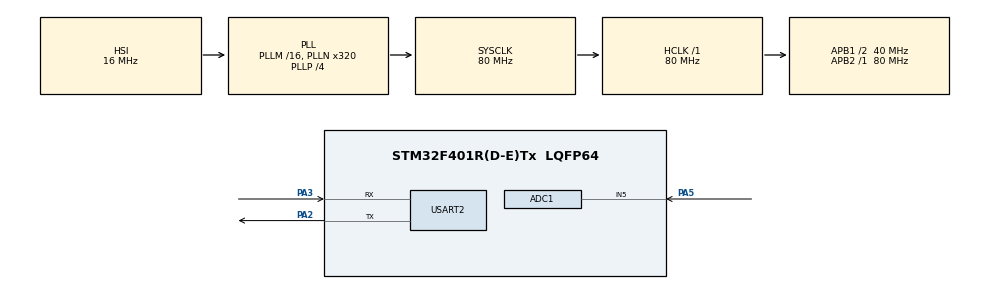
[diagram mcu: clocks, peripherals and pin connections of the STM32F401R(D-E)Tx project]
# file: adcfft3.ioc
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ADC1.Channel-1\#ChannelRegularConversion=ADC_CHANNEL_5
ADC1.ExternalTrigConv=ADC_EXTERNALTRIGCONV_T2_TRGO
ADC1.NbrOfConversionFlag=1
ADC1.Rank-1\#ChannelRegularConversion=1
ADC1.SamplingTime-1\#ChannelRegularConversion=ADC_SAMPLETIME_3CYCLES
ADC1.master=1
Mcu.Family=STM32F4
Mcu.Name=STM32F401R(D-E)Tx
Mcu.Package=LQFP64
NVIC.ADC_IRQn=true\:0\:0\:false\:false\:true\:true\:true\:true
NVIC.PriorityGroup=NVIC_PRIORITYGROUP_4
NVIC.TIM2_IRQn=true\:0\:0\:false\:false\:true\:true\:true\:true
NVIC.TIM3_IRQn=true\:0\:0\:false\:false\:true\:true\:true\:true
PA2.Mode=Asynchronous
PA2.Signal=USART2_TX
PA3.Mode=Asynchronous
PA3.Signal=USART2_RX
PA5.Signal=ADCx_IN5
ProjectManager.HeapSize=0x200
ProjectManager.StackSize=0x400
ProjectManager.TargetToolchain=STM32CubeIDE
RCC.48MHZClocksFreq_Value=80000000
RCC.AHBFreq_Value=80000000
RCC.APB1CLKDivider=RCC_HCLK_DIV2
RCC.APB1Freq_Value=40000000
RCC.APB1TimFreq_Value=80000000
RCC.APB2Freq_Value=80000000
RCC.APB2TimFreq_Value=80000000
RCC.CortexFreq_Value=80000000
RCC.HCLKFreq_Value=80000000
RCC.HSE_VALUE=25000000
RCC.HSI_VALUE=16000000
RCC.LSE_VALUE=32768
RCC.PLLN=320
RCC.PLLP=RCC_PLLP_DIV4
RCC.SYSCLKFreq_VALUE=80000000
RCC.SYSCLKSource=RCC_SYSCLKSOURCE_PLLCLK
RCC.VCOOutputFreq_Value=320000000
SH.ADCx_IN5.0=ADC1_IN5,IN5
TIM2.Channel-PWM\ Generation1\ No\ Output=TIM_CHANNEL_1
TIM2.Period=400
TIM2.TIM_MasterOutputTrigger=TIM_TRGO_UPDATE
TIM2.TIM_MasterSlaveMode=TIM_MASTERSLAVEMODE_DISABLE
TIM3.ClockDivision=TIM_CLOCKDIVISION_DIV4
TIM3.Period=40960
TIM3.Prescaler=7
USART2.VirtualMode=VM_ASYNC
VP_TIM2_VS_ClockSourceINT.Mode=Internal
VP_TIM2_VS_no_output1.Mode=PWM Generation1 No Output
VP_TIM3_VS_ClockSourceINT.Mode=Internal
board=custom

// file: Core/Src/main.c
/* USER CODE BEGIN Header */
/**
  ******************************************************************************
  * @file           : main.c
  * @brief          : Main program body
  ******************************************************************************
  * @attention
  *
  * Copyright (c) 2025 STMicroelectronics.
  * All rights reserved.
  *
  * This software is licensed under terms that can be found in the LICENSE file
  * in the root directory of this software component.
  * If no LICENSE file comes with this software, it is provided AS-IS.
  *
  ******************************************************************************
  */
/* USER CODE END Header */
#include "main.h"

/* USER CODE BEGIN Includes */
#include "stdbool.h"
#include <string.h>
#include "arm_math.h"
#include "stm32f4xx_it.h"
#include "string.h"
/* USER CODE END Includes */

ADC_HandleTypeDef hadc1;

TIM_HandleTypeDef htim2;
TIM_HandleTypeDef htim3;

UART_HandleTypeDef huart2;

/* USER CODE BEGIN PV */
extern int val_from_adc;
extern float32_t adc_val_array1[FFT_N];
extern float32_t adc_val_array2[FFT_N];
extern bool inputtingarray2;
extern uint32_t adc_arrayindex;
extern bool timer3calcfft;

int message[MESSAGE_LENGTH];
uint32_t messageindex;
float32_t fft_val_array[2* FFT_N];
float32_t fft_val_array_magnitude[FFT_N];
/* USER CODE END PV */

void SystemClock_Config(void);
static void MX_GPIO_Init(void);
static void MX_ADC1_Init(void);
static void MX_TIM2_Init(void);
static void MX_TIM3_Init(void);
static void MX_USART2_UART_Init(void);

/* USER CODE BEGIN 0 */
int _write(int file, char *ptr, int len) {
  /* Implement your write code here, this is used by puts and printf for example */
  int i=0;
  for(i=0 ; i<len ; i++)
  ITM_SendChar((*ptr++));
  return len;
}

/* USER CODE END 0 */

int main(void)
{

  /* MCU Configuration--------------------------------------------------------*/

  /* Reset of all peripherals, Initializes the Flash interface and the Systick. */
  HAL_Init();

  /* Configure the system clock */
  SystemClock_Config();

  /* Initialize all configured peripherals */
  MX_GPIO_Init();
  MX_ADC1_Init();
  MX_TIM2_Init();
  MX_TIM3_Init();
  MX_USART2_UART_Init();
  /* USER CODE BEGIN 2 */
  HAL_ADC_Start_IT(&hadc1);
  HAL_TIM_Base_Start_IT(&htim2);
  HAL_TIM_Base_Start_IT(&htim3);

  arm_cfft_instance_f32 S;
//  uint32_t fftSize = FFT_N;
  uint32_t ifftFlag = 0;
  uint32_t doBitReverse = 1;

//  uint32_t testIndex = 0;
//  float32_t maxValue;

//  arm_status status = arm_cfft_radix4_init_f32 (&S, fftSize, ifftFlag, doBitReverse);
  arm_cfft_init_f32(&S, FFT_N);
  messageindex = 0;

  while(!inputtingarray2); // first time inputting into array 1 (not necessary)

  /* USER CODE END 2 */

  /* Infinite loop */
  while (1)
  {

    /* USER CODE BEGIN 3 */
	if (timer3calcfft) {
//	  memset(fft_val_array, 0, FFT_N * sizeof(fft_val_array[0]));
	  if (inputtingarray2) {
//		memcpy(fft_val_array, adc_val_array1, FFT_N * sizeof(adc_val_array1[0]));
		for (int i = 0; i < FFT_N; i++) {
          fft_val_array[2*i] = adc_val_array1[i];
          fft_val_array[2*i + 1] = 0;
		}
	  } else {
//		memcpy(fft_val_array, adc_val_array2, FFT_N * sizeof(adc_val_array2[0]));
	    for (int i = 0; i < FFT_N; i++) {
		  fft_val_array[2*i] = adc_val_array2[i];
          fft_val_array[2*i + 1] = 0;
		}
	  }
	  arm_cfft_f32(&S, fft_val_array, ifftFlag, doBitReverse);
	  arm_cmplx_mag_f32(fft_val_array, fft_val_array_magnitude, FFT_N);
//	  arm_cfft_radix4_f32 (&S, fft_val_array);                      // FFT transform
//	  arm_cmplx_mag_f32 (fft_val_array, fft_val_array_magnitude, fftSize);       // recalculate to Magn./Phase representation
//	  arm_max_f32 (fft_val_array_magnitude, fftSize, &maxValue, &testIndex); // find maxValue and returns it's index (bin) value
	  timer3calcfft = 0;

	  if (messageindex <= MESSAGE_LENGTH) {
		int bit0twotrue = ((fft_val_array_magnitude[FREQ0INDEX2] > RECEIVE0THRESHOLDTWO) ? 1:0) +
				((fft_val_array_magnitude[FREQ0INDEX3] > RECEIVE0THRESHOLDTWO) ? 1:0) +
				((fft_val_array_magnitude[FREQ0INDEX4] > RECEIVE0THRESHOLDTWO) ? 1:0);
		int bit1twotrue = (fft_val_array_magnitude[FREQ1INDEX1] > RECEIVE1THRESHOLD) ? 1:0 +
	    		(fft_val_array_magnitude[FREQ1INDEX2] > RECEIVE1THRESHOLDTWO) ? 1:0 +
				(fft_val_array_magnitude[FREQ1INDEX3] > RECEIVE1THRESHOLDTWO) ? 1:0 +
				(fft_val_array_magnitude[FREQ1INDEX4] > RECEIVE1THRESHOLDTWO) ? 1:0 +
				(fft_val_array_magnitude[FREQ1INDEX5] > RECEIVE1THRESHOLDTWO) ? 1:0;
	    if ((fft_val_array_magnitude[FREQ0INDEX1] > RECEIVE0THRESHOLD) || bit0twotrue >= 2) {
		  message[messageindex] = 0;
		  messageindex++;

		  char buffer[] = "Bit: 0\r\n";
		  HAL_UART_Transmit(&huart2, (uint8_t*)buffer, strlen(buffer), HAL_MAX_DELAY);
	    } else if ((fft_val_array_magnitude[FREQ1INDEX1] > RECEIVE0THRESHOLD) || bit1twotrue >= 1) {
		  message[messageindex] = 1;
		  messageindex++;

		  char buffer[] = "Bit: 1\r\n";

		  HAL_UART_Transmit(&huart2, (uint8_t*)buffer, strlen(buffer), HAL_MAX_DELAY);
	    } else {
	      message[messageindex] = -1;
	      messageindex++;

	      char buffer[] = "Bit: -1\r\n";

		  HAL_UART_Transmit(&huart2, (uint8_t*)buffer, strlen(buffer), HAL_MAX_DELAY);
	    }
	  }
	}
  }
  /* USER CODE END 3 */
}

void SystemClock_Config(void)
{
  RCC_OscInitTypeDef RCC_OscInitStruct = {0};
  RCC_ClkInitTypeDef RCC_ClkInitStruct = {0};

  /** Configure the main internal regulator output voltage
  */
  __HAL_RCC_PWR_CLK_ENABLE();
  __HAL_PWR_VOLTAGESCALING_CONFIG(PWR_REGULATOR_VOLTAGE_SCALE2);

  /** Initializes the RCC Oscillators according to the specified parameters
  * in the RCC_OscInitTypeDef structure.
  */
  RCC_OscInitStruct.OscillatorType = RCC_OSCILLATORTYPE_HSI;
  RCC_OscInitStruct.HSIState = RCC_HSI_ON;
  RCC_OscInitStruct.HSICalibrationValue = RCC_HSICALIBRATION_DEFAULT;
  RCC_OscInitStruct.PLL.PLLState = RCC_PLL_ON;
  RCC_OscInitStruct.PLL.PLLSource = RCC_PLLSOURCE_HSI;
  RCC_OscInitStruct.PLL.PLLM = 16;
  RCC_OscInitStruct.PLL.PLLN = 320;
  RCC_OscInitStruct.PLL.PLLP = RCC_PLLP_DIV4;
  RCC_OscInitStruct.PLL.PLLQ = 4;
  if (HAL_RCC_OscConfig(&RCC_OscInitStruct) != HAL_OK)
  {
    Error_Handler();
  }

  /** Initializes the CPU, AHB and APB buses clocks
  */
  RCC_ClkInitStruct.ClockType = RCC_CLOCKTYPE_HCLK|RCC_CLOCKTYPE_SYSCLK
                              |RCC_CLOCKTYPE_PCLK1|RCC_CLOCKTYPE_PCLK2;
  RCC_ClkInitStruct.SYSCLKSource = RCC_SYSCLKSOURCE_PLLCLK;
  RCC_ClkInitStruct.AHBCLKDivider = RCC_SYSCLK_DIV1;
  RCC_ClkInitStruct.APB1CLKDivider = RCC_HCLK_DIV2;
  RCC_ClkInitStruct.APB2CLKDivider = RCC_HCLK_DIV1;

  if (HAL_RCC_ClockConfig(&RCC_ClkInitStruct, FLASH_LATENCY_2) != HAL_OK)
  {
    Error_Handler();
  }
}

static void MX_ADC1_Init(void)
{

  ADC_ChannelConfTypeDef sConfig = {0};

  /** Configure the global features of the ADC (Clock, Resolution, Data Alignment and number of conversion)
  */
  hadc1.Instance = ADC1;
  hadc1.Init.ClockPrescaler = ADC_CLOCK_SYNC_PCLK_DIV4;
  hadc1.Init.Resolution = ADC_RESOLUTION_12B;
  hadc1.Init.ScanConvMode = DISABLE;
  hadc1.Init.ContinuousConvMode = DISABLE;
  hadc1.Init.DiscontinuousConvMode = DISABLE;
  hadc1.Init.ExternalTrigConvEdge = ADC_EXTERNALTRIGCONVEDGE_RISING;
  hadc1.Init.ExternalTrigConv = ADC_EXTERNALTRIGCONV_T2_TRGO;
  hadc1.Init.DataAlign = ADC_DATAALIGN_RIGHT;
  hadc1.Init.NbrOfConversion = 1;
  hadc1.Init.DMAContinuousRequests = DISABLE;
  hadc1.Init.EOCSelection = ADC_EOC_SINGLE_CONV;
  if (HAL_ADC_Init(&hadc1) != HAL_OK)
  {
    Error_Handler();
  }

  /** Configure for the selected ADC regular channel its corresponding rank in the sequencer and its sample time.
  */
  sConfig.Channel = ADC_CHANNEL_5;
  sConfig.Rank = 1;
  sConfig.SamplingTime = ADC_SAMPLETIME_3CYCLES;
  if (HAL_ADC_ConfigChannel(&hadc1, &sConfig) != HAL_OK)
  {
    Error_Handler();
  }

}

static void MX_TIM2_Init(void)
{

  TIM_ClockConfigTypeDef sClockSourceConfig = {0};
  TIM_MasterConfigTypeDef sMasterConfig = {0};
  TIM_OC_InitTypeDef sConfigOC = {0};

  htim2.Instance = TIM2;
  htim2.Init.Prescaler = 0;
  htim2.Init.CounterMode = TIM_COUNTERMODE_UP;
  htim2.Init.Period = 400;
  htim2.Init.ClockDivision = TIM_CLOCKDIVISION_DIV1;
  htim2.Init.AutoReloadPreload = TIM_AUTORELOAD_PRELOAD_DISABLE;
  if (HAL_TIM_Base_Init(&htim2) != HAL_OK)
  {
    Error_Handler();
  }
  sClockSourceConfig.ClockSource = TIM_CLOCKSOURCE_INTERNAL;
  if (HAL_TIM_ConfigClockSource(&htim2, &sClockSourceConfig) != HAL_OK)
  {
    Error_Handler();
  }
  if (HAL_TIM_PWM_Init(&htim2) != HAL_OK)
  {
    Error_Handler();
  }
  sMasterConfig.MasterOutputTrigger = TIM_TRGO_UPDATE;
  sMasterConfig.MasterSlaveMode = TIM_MASTERSLAVEMODE_DISABLE;
  if (HAL_TIMEx_MasterConfigSynchronization(&htim2, &sMasterConfig) != HAL_OK)
  {
    Error_Handler();
  }
  sConfigOC.OCMode = TIM_OCMODE_PWM1;
  sConfigOC.Pulse = 0;
  sConfigOC.OCPolarity = TIM_OCPOLARITY_HIGH;
  sConfigOC.OCFastMode = TIM_OCFAST_DISABLE;
  if (HAL_TIM_PWM_ConfigChannel(&htim2, &sConfigOC, TIM_CHANNEL_1) != HAL_OK)
  {
    Error_Handler();
  }
  /* USER CODE BEGIN TIM2_Init 2 */
  HAL_NVIC_SetPriority(TIM2_IRQn, 0, 0);
  HAL_NVIC_EnableIRQ(TIM2_IRQn);
  /* USER CODE END TIM2_Init 2 */

}

static void MX_TIM3_Init(void)
{

  TIM_ClockConfigTypeDef sClockSourceConfig = {0};
  TIM_MasterConfigTypeDef sMasterConfig = {0};

  htim3.Instance = TIM3;
  htim3.Init.Prescaler = 7;
  htim3.Init.CounterMode = TIM_COUNTERMODE_UP;
  htim3.Init.Period = 40960;
  htim3.Init.ClockDivision = TIM_CLOCKDIVISION_DIV4;
  htim3.Init.AutoReloadPreload = TIM_AUTORELOAD_PRELOAD_DISABLE;
  if (HAL_TIM_Base_Init(&htim3) != HAL_OK)
  {
    Error_Handler();
  }
  sClockSourceConfig.ClockSource = TIM_CLOCKSOURCE_INTERNAL;
  if (HAL_TIM_ConfigClockSource(&htim3, &sClockSourceConfig) != HAL_OK)
  {
    Error_Handler();
  }
  sMasterConfig.MasterOutputTrigger = TIM_TRGO_RESET;
  sMasterConfig.MasterSlaveMode = TIM_MASTERSLAVEMODE_DISABLE;
  if (HAL_TIMEx_MasterConfigSynchronization(&htim3, &sMasterConfig) != HAL_OK)
  {
    Error_Handler();
  }
  /* USER CODE BEGIN TIM3_Init 2 */
  HAL_NVIC_SetPriority(TIM3_IRQn, 1, 1);
  HAL_NVIC_EnableIRQ(TIM3_IRQn);
  /* USER CODE END TIM3_Init 2 */

}

static void MX_USART2_UART_Init(void)
{

  huart2.Instance = USART2;
  huart2.Init.BaudRate = 115200;
  huart2.Init.WordLength = UART_WORDLENGTH_8B;
  huart2.Init.StopBits = UART_STOPBITS_1;
  huart2.Init.Parity = UART_PARITY_NONE;
  huart2.Init.Mode = UART_MODE_TX_RX;
  huart2.Init.HwFlowCtl = UART_HWCONTROL_NONE;
  huart2.Init.OverSampling = UART_OVERSAMPLING_16;
  if (HAL_UART_Init(&huart2) != HAL_OK)
  {
    Error_Handler();
  }

}

static void MX_GPIO_Init(void)
{

  /* GPIO Ports Clock Enable */
  __HAL_RCC_GPIOA_CLK_ENABLE();

}

void Error_Handler(void)
{
  __disable_irq();
  while (1)
  {
  }
}
